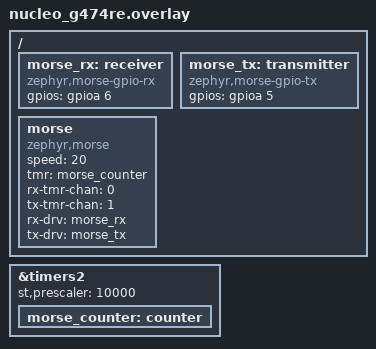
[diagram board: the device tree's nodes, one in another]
/*
 * Copyright (c) 2024-2026 Freedom Veiculos Eletricos
 * Copyright (c) 2024-2026 O.S. Systems Software LTDA.
 *
 * SPDX-License-Identifier: Apache-2.0
 */

/ {
	/* arduino.pd12 */
	morse_rx: receiver {
		compatible = "zephyr,morse-gpio-rx";

		gpios = <&gpioa 6 GPIO_ACTIVE_HIGH>;
	};

	/* arduino.pd13 */
	morse_tx: transmitter {
		compatible = "zephyr,morse-gpio-tx";

		gpios = <&gpioa 5 GPIO_ACTIVE_HIGH>;
	};

	morse: morse {
		compatible = "zephyr,morse";
		status = "okay";

		speed = <20>;
		tmr = <&morse_counter>;

		rx-tmr-chan = <0>;
		tx-tmr-chan = <1>;

		rx-drv = <&morse_rx>;
		tx-drv = <&morse_tx>;
	};
};

&timers2 {
	st,prescaler = <10000>;
	status = "okay";

	morse_counter: counter {
		status = "okay";
	};
};
